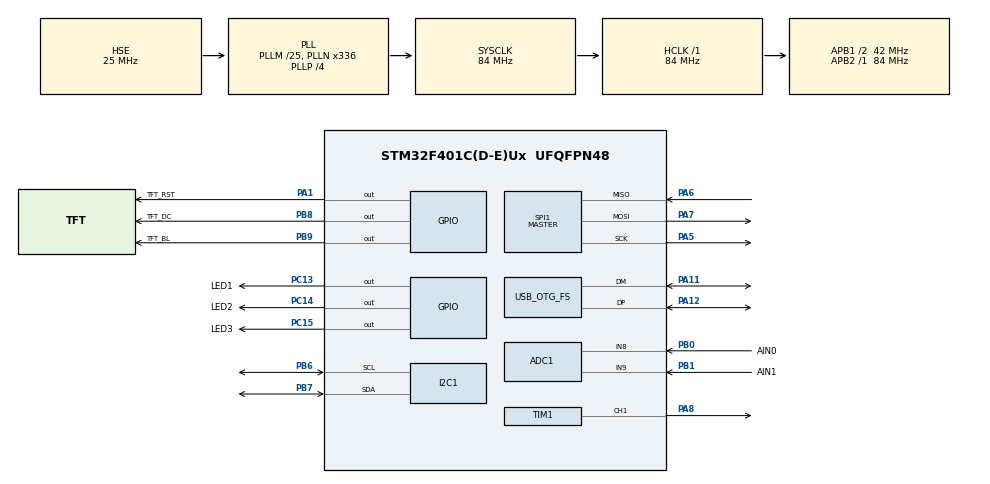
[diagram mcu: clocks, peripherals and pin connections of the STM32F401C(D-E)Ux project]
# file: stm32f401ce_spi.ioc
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ADC1.Channel-0\#ChannelRegularConversion=ADC_CHANNEL_8
ADC1.Channel-1\#ChannelRegularConversion=ADC_CHANNEL_9
ADC1.DMAContinuousRequests=ENABLE
ADC1.EOCSelection=ADC_EOC_SEQ_CONV
ADC1.ExternalTrigConv=ADC_EXTERNALTRIGCONV_T1_CC1
ADC1.NbrOfConversion=2
ADC1.NbrOfConversionFlag=1
ADC1.Rank-0\#ChannelRegularConversion=1
ADC1.Rank-1\#ChannelRegularConversion=2
ADC1.SamplingTime-0\#ChannelRegularConversion=ADC_SAMPLETIME_3CYCLES
ADC1.SamplingTime-1\#ChannelRegularConversion=ADC_SAMPLETIME_3CYCLES
ADC1.master=1
Dma.ADC1.0.Direction=DMA_PERIPH_TO_MEMORY
Dma.ADC1.0.FIFOMode=DMA_FIFOMODE_ENABLE
Dma.ADC1.0.FIFOThreshold=DMA_FIFO_THRESHOLD_HALFFULL
Dma.ADC1.0.Instance=DMA2_Stream0
Dma.ADC1.0.MemBurst=DMA_MBURST_SINGLE
Dma.ADC1.0.MemDataAlignment=DMA_MDATAALIGN_HALFWORD
Dma.ADC1.0.MemInc=DMA_MINC_ENABLE
Dma.ADC1.0.Mode=DMA_CIRCULAR
Dma.ADC1.0.PeriphBurst=DMA_PBURST_SINGLE
Dma.ADC1.0.PeriphDataAlignment=DMA_PDATAALIGN_HALFWORD
Dma.ADC1.0.PeriphInc=DMA_PINC_DISABLE
Dma.ADC1.0.Priority=DMA_PRIORITY_LOW
Dma.Request0=ADC1
Dma.Request1=SPI1_TX
Dma.SPI1_TX.1.Direction=DMA_MEMORY_TO_PERIPH
Dma.SPI1_TX.1.FIFOMode=DMA_FIFOMODE_DISABLE
Dma.SPI1_TX.1.Instance=DMA2_Stream3
Dma.SPI1_TX.1.MemDataAlignment=DMA_MDATAALIGN_BYTE
Dma.SPI1_TX.1.MemInc=DMA_MINC_ENABLE
Dma.SPI1_TX.1.Mode=DMA_NORMAL
Dma.SPI1_TX.1.PeriphDataAlignment=DMA_PDATAALIGN_BYTE
Dma.SPI1_TX.1.PeriphInc=DMA_PINC_DISABLE
Dma.SPI1_TX.1.Priority=DMA_PRIORITY_MEDIUM
Mcu.Family=STM32F4
Mcu.Name=STM32F401C(D-E)Ux
Mcu.Package=UFQFPN48
NVIC.DMA2_Stream0_IRQn=true\:0\:0\:false\:false\:true\:false\:true
NVIC.DMA2_Stream3_IRQn=true\:0\:0\:false\:false\:true\:false\:true
NVIC.OTG_FS_IRQn=true\:0\:0\:false\:false\:true\:false\:true
NVIC.PriorityGroup=NVIC_PRIORITYGROUP_4
PA1.GPIO_Label=TFT_RST
PA1.GPIO_Speed=GPIO_SPEED_FREQ_VERY_HIGH
PA1.Signal=GPIO_Output
PA11.Mode=Device_Only
PA11.Signal=USB_OTG_FS_DM
PA12.Mode=Device_Only
PA12.Signal=USB_OTG_FS_DP
PA13.Mode=Trace_Asynchronous_SW
PA13.Signal=SYS_JTMS-SWDIO
PA14.Mode=Trace_Asynchronous_SW
PA14.Signal=SYS_JTCK-SWCLK
PA5.Mode=Full_Duplex_Master
PA5.Signal=SPI1_SCK
PA6.Mode=Full_Duplex_Master
PA6.Signal=SPI1_MISO
PA7.Mode=Full_Duplex_Master
PA7.Signal=SPI1_MOSI
PA8.Signal=S_TIM1_CH1
PB0.GPIO_Label=AIN0
PB0.Signal=ADCx_IN8
PB1.GPIO_Label=AIN1
PB1.Signal=ADCx_IN9
PB3.Mode=Trace_Asynchronous_SW
PB3.Signal=SYS_JTDO-SWO
PB6.Mode=I2C
PB6.Signal=I2C1_SCL
PB7.Mode=I2C
PB7.Signal=I2C1_SDA
PB8.GPIO_Label=TFT_DC
PB8.GPIO_Speed=GPIO_SPEED_FREQ_VERY_HIGH
PB8.Signal=GPIO_Output
PB9.GPIO_Label=TFT_BL
PB9.GPIO_Speed=GPIO_SPEED_FREQ_VERY_HIGH
PB9.Signal=GPIO_Output
PC13-ANTI_TAMP.GPIO_Label=LED1
PC13-ANTI_TAMP.Signal=GPIO_Output
PC14-OSC32_IN.GPIO_Label=LED2
PC14-OSC32_IN.Signal=GPIO_Output
PC15-OSC32_OUT.GPIO_Label=LED3
PC15-OSC32_OUT.Signal=GPIO_Output
PH0\ -\ OSC_IN.Mode=HSE-External-Oscillator
PH0\ -\ OSC_IN.Signal=RCC_OSC_IN
PH1\ -\ OSC_OUT.Mode=HSE-External-Oscillator
PH1\ -\ OSC_OUT.Signal=RCC_OSC_OUT
ProjectManager.HeapSize=0x200
ProjectManager.StackSize=0x400
ProjectManager.TargetToolchain=STM32CubeIDE
RCC.48MHZClocksFreq_Value=48000000
RCC.AHBFreq_Value=84000000
RCC.APB1CLKDivider=RCC_HCLK_DIV2
RCC.APB1Freq_Value=42000000
RCC.APB1TimFreq_Value=84000000
RCC.APB2Freq_Value=84000000
RCC.APB2TimFreq_Value=84000000
RCC.CortexFreq_Value=84000000
RCC.HCLKFreq_Value=84000000
RCC.HSE_VALUE=25000000
RCC.HSI_VALUE=16000000
RCC.LSE_VALUE=32768
RCC.PLLM=25
RCC.PLLN=336
RCC.PLLP=RCC_PLLP_DIV4
RCC.PLLQ=7
RCC.SYSCLKFreq_VALUE=84000000
RCC.SYSCLKSource=RCC_SYSCLKSOURCE_PLLCLK
RCC.VCOOutputFreq_Value=336000000
SH.ADCx_IN8.0=ADC1_IN8,IN8
SH.ADCx_IN9.0=ADC1_IN9,IN9
SH.S_TIM1_CH1.0=TIM1_CH1,PWM Generation1 CH1
SPI1.Direction=SPI_DIRECTION_2LINES
SPI1.Mode=SPI_MODE_MASTER
SPI1.VirtualType=VM_MASTER
TIM1.Channel-PWM\ Generation1\ CH1=TIM_CHANNEL_1
TIM1.Period=840-1
TIM1.Pulse-PWM\ Generation1\ CH1=84-1
TIM1.TIM_MasterOutputTrigger=TIM_TRGO_OC1
USB_DEVICE.CLASS_NAME_FS=CDC
USB_DEVICE.VirtualMode=Cdc
USB_DEVICE.VirtualMode-CDC_FS=Cdc
USB_DEVICE.VirtualModeFS=Cdc_FS
USB_OTG_FS.VirtualMode=Device_Only
VP_TIM1_VS_ClockSourceINT.Mode=Internal
VP_USB_DEVICE_VS_USB_DEVICE_CDC_FS.Mode=CDC_FS
board=custom

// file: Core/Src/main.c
/* USER CODE BEGIN Header */
/**
  ******************************************************************************
  * @file           : main.c
  * @brief          : Main program body
  ******************************************************************************
  * @attention
  *
  * <h2><center>&copy; Copyright (c) 2021 STMicroelectronics.
  * All rights reserved.</center></h2>
  *
  * This software component is licensed by ST under Ultimate Liberty license
  * SLA0044, the "License"; You may not use this file except in compliance with
  * the License. You may obtain a copy of the License at:
  *                             www.st.com/SLA0044
  *
  ******************************************************************************
  */
/* USER CODE END Header */
#include "main.h"
#include "adc.h"
#include "dma.h"
#include "i2c.h"
#include "spi.h"
#include "tim.h"
#include "usb_device.h"
#include "gpio.h"

/* USER CODE BEGIN Includes */

#include "test.h"

/* USER CODE END Includes */

void SystemClock_Config(void);

/* USER CODE BEGIN 0 */

//static uint8_t test_data[100];

/* USER CODE END 0 */

int main(void)
{
  /* USER CODE BEGIN 1 */

	//for (int i = 0; i < sizeof(test_data); i++) {
	//	test_data[i] = i;
	//}

  /* USER CODE END 1 */

  /* MCU Configuration--------------------------------------------------------*/

  /* Reset of all peripherals, Initializes the Flash interface and the Systick. */
  HAL_Init();

  /* Configure the system clock */
  SystemClock_Config();

  /* Initialize all configured peripherals */
  MX_GPIO_Init();
  MX_DMA_Init();
  MX_ADC1_Init();
  MX_TIM1_Init();
  MX_USB_DEVICE_Init();
  MX_I2C1_Init();
  MX_SPI1_Init();
  /* USER CODE BEGIN 2 */

  //HAL_SPI_

//	tft_init();

  /* USER CODE END 2 */

  /* Infinite loop */
  /* USER CODE BEGIN WHILE */
  while (1)
  {

  	LED1_ON;
  	tft_init();
    LED1_OFF;

  	HAL_Delay(500);
    /* USER CODE END WHILE */

    /* USER CODE BEGIN 3 */

  	//HAL_StatusTypeDef status = HAL_SPI_Transmit_DMA(&hspi1, test_data, sizeof(test_data));
//
  	//printf("Status: %d\n", status);
    //HAL_Delay(500);

  }
  /* USER CODE END 3 */
}

void SystemClock_Config(void)
{
  RCC_OscInitTypeDef RCC_OscInitStruct = {0};
  RCC_ClkInitTypeDef RCC_ClkInitStruct = {0};

  /** Configure the main internal regulator output voltage
  */
  __HAL_RCC_PWR_CLK_ENABLE();
  __HAL_PWR_VOLTAGESCALING_CONFIG(PWR_REGULATOR_VOLTAGE_SCALE2);
  /** Initializes the RCC Oscillators according to the specified parameters
  * in the RCC_OscInitTypeDef structure.
  */
  RCC_OscInitStruct.OscillatorType = RCC_OSCILLATORTYPE_HSE;
  RCC_OscInitStruct.HSEState = RCC_HSE_ON;
  RCC_OscInitStruct.PLL.PLLState = RCC_PLL_ON;
  RCC_OscInitStruct.PLL.PLLSource = RCC_PLLSOURCE_HSE;
  RCC_OscInitStruct.PLL.PLLM = 25;
  RCC_OscInitStruct.PLL.PLLN = 336;
  RCC_OscInitStruct.PLL.PLLP = RCC_PLLP_DIV4;
  RCC_OscInitStruct.PLL.PLLQ = 7;
  if (HAL_RCC_OscConfig(&RCC_OscInitStruct) != HAL_OK)
  {
    Error_Handler();
  }
  /** Initializes the CPU, AHB and APB buses clocks
  */
  RCC_ClkInitStruct.ClockType = RCC_CLOCKTYPE_HCLK|RCC_CLOCKTYPE_SYSCLK
                              |RCC_CLOCKTYPE_PCLK1|RCC_CLOCKTYPE_PCLK2;
  RCC_ClkInitStruct.SYSCLKSource = RCC_SYSCLKSOURCE_PLLCLK;
  RCC_ClkInitStruct.AHBCLKDivider = RCC_SYSCLK_DIV1;
  RCC_ClkInitStruct.APB1CLKDivider = RCC_HCLK_DIV2;
  RCC_ClkInitStruct.APB2CLKDivider = RCC_HCLK_DIV1;

  if (HAL_RCC_ClockConfig(&RCC_ClkInitStruct, FLASH_LATENCY_2) != HAL_OK)
  {
    Error_Handler();
  }
}

void Error_Handler(void)
{
}

/************************ (C) COPYRIGHT STMicroelectronics *****END OF FILE****/
